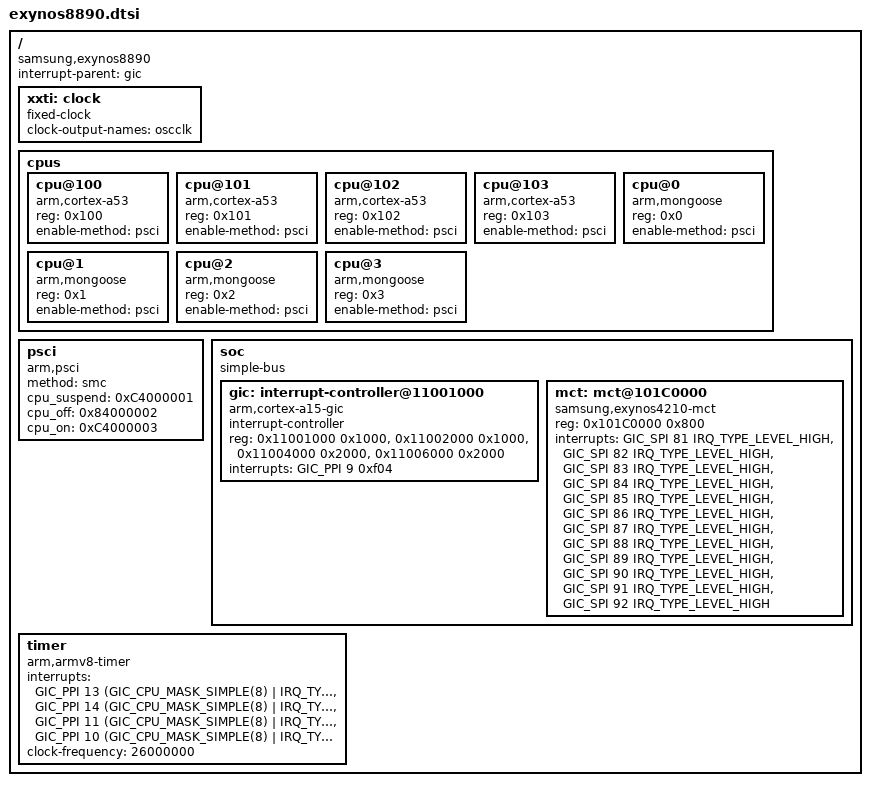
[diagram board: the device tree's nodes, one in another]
// SPDX-License-Identifier: GPL-2.0
/*
 * SAMSUNG EXYNOS8890 SoC device tree source
 */
/dts-v1/;
#include <dt-bindings/interrupt-controller/arm-gic.h>

/ {
	compatible = "samsung,exynos8890";
	#address-cells = <2>;
	#size-cells = <2>;

	interrupt-parent = <&gic>;

	xxti: clock {
		/* XXTI */
		compatible = "fixed-clock";
		clock-output-names = "oscclk";
		#clock-cells = <0>;
	};

	cpus {
        #address-cells = <1>;
		#size-cells = <0>;

		cpu@100 {
			device_type = "cpu";
			compatible = "arm,cortex-a53", "arm,armv8";
			reg = <0x100>;
			enable-method = "psci";
		};
		cpu@101 {
			device_type = "cpu";
			compatible = "arm,cortex-a53", "arm,armv8";
			reg = <0x101>;
			enable-method = "psci";
		};
		cpu@102 {
			device_type = "cpu";
			compatible = "arm,cortex-a53", "arm,armv8";
			reg = <0x102>;
			enable-method = "psci";
		};
		cpu@103 {
			device_type = "cpu";
			compatible = "arm,cortex-a53", "arm,armv8";
			reg = <0x103>;
			enable-method = "psci";
		};
		cpu@0 {
			device_type = "cpu";
			compatible = "arm,mongoose", "arm,armv8";
			reg = <0x0>;
			enable-method = "psci";
		};
		cpu@1 {
			device_type = "cpu";
			compatible = "arm,mongoose", "arm,armv8";
			reg = <0x1>;
			enable-method = "psci";
		};
		cpu@2 {
			device_type = "cpu";
			compatible = "arm,mongoose", "arm,armv8";
			reg = <0x2>;
			enable-method = "psci";
		};
		cpu@3 {
			device_type = "cpu";
			compatible = "arm,mongoose", "arm,armv8";
			reg = <0x3>;
			enable-method = "psci";
		};
	};

	psci {
		compatible = "arm,psci";
		method = "smc";
		cpu_suspend = <0xC4000001>;
		cpu_off = <0x84000002>;
		cpu_on = <0xC4000003>;
	};

	soc: soc {
		compatible = "simple-bus";
		#address-cells = <1>;
		#size-cells = <1>;
		ranges = <0 0 0 0x18000000>;

		gic: interrupt-controller@11001000 {
			compatible = "arm,cortex-a15-gic";
			#interrupt-cells = <3>;
			interrupt-controller;
			reg = <0x11001000 0x1000>,
			      <0x11002000 0x1000>,
			      <0x11004000 0x2000>,
			      <0x11006000 0x2000>;
			interrupts = <GIC_PPI 9 0xf04>;
		};

		mct: mct@101C0000 {
			compatible = "samsung,exynos4210-mct";
			reg = <0x101C0000 0x800>;
			interrupts = <GIC_SPI 81 IRQ_TYPE_LEVEL_HIGH>,
				<GIC_SPI 82 IRQ_TYPE_LEVEL_HIGH>,
				<GIC_SPI 83 IRQ_TYPE_LEVEL_HIGH>,
				<GIC_SPI 84 IRQ_TYPE_LEVEL_HIGH>,
				<GIC_SPI 85 IRQ_TYPE_LEVEL_HIGH>,
				<GIC_SPI 86 IRQ_TYPE_LEVEL_HIGH>,
				<GIC_SPI 87 IRQ_TYPE_LEVEL_HIGH>,
				<GIC_SPI 88 IRQ_TYPE_LEVEL_HIGH>,
				<GIC_SPI 89 IRQ_TYPE_LEVEL_HIGH>,
				<GIC_SPI 90 IRQ_TYPE_LEVEL_HIGH>,
				<GIC_SPI 91 IRQ_TYPE_LEVEL_HIGH>,
				<GIC_SPI 92 IRQ_TYPE_LEVEL_HIGH>;
            
			// TODO clocks
			//clocks = <&xxti>, <&cmu_peris CLK_PCLK_MCT>;
			//clock-names = "fin_pll", "mct";
		};
	};

	timer: timer {
		compatible = "arm,armv8-timer";
		interrupts = <GIC_PPI 13
				(GIC_CPU_MASK_SIMPLE(8) | IRQ_TYPE_LEVEL_HIGH)>,
			<GIC_PPI 14
				(GIC_CPU_MASK_SIMPLE(8) | IRQ_TYPE_LEVEL_HIGH)>,
			<GIC_PPI 11
				(GIC_CPU_MASK_SIMPLE(8) | IRQ_TYPE_LEVEL_HIGH)>,
			<GIC_PPI 10
				(GIC_CPU_MASK_SIMPLE(8) | IRQ_TYPE_LEVEL_HIGH)>;
		clock-frequency = <26000000>;
	};
};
